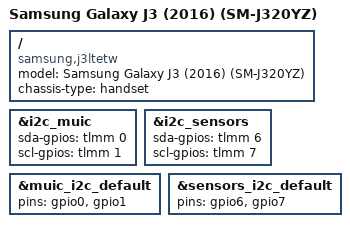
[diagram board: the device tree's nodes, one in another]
// SPDX-License-Identifier: GPL-2.0-only

/dts-v1/;

#include "msm8916-samsung-j3-common.dtsi"

/ {
	model = "Samsung Galaxy J3 (2016) (SM-J320YZ)";
	compatible = "samsung,j3ltetw", "qcom,msm8916";
	chassis-type = "handset";
};

&i2c_muic {
	sda-gpios = <&tlmm 0 (GPIO_ACTIVE_HIGH|GPIO_OPEN_DRAIN)>;
	scl-gpios = <&tlmm 1 (GPIO_ACTIVE_HIGH|GPIO_OPEN_DRAIN)>;
};

&i2c_sensors {
	/* I2C2 */
	sda-gpios = <&tlmm 6 (GPIO_ACTIVE_HIGH|GPIO_OPEN_DRAIN)>;
	scl-gpios = <&tlmm 7 (GPIO_ACTIVE_HIGH|GPIO_OPEN_DRAIN)>;
};

&muic_i2c_default {
	pins = "gpio0", "gpio1";
};

&sensors_i2c_default {
	/* I2C2 */
	pins = "gpio6", "gpio7";
};
